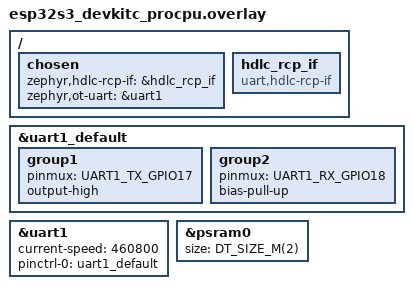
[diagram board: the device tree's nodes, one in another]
/*
 * Copyright (c) 2026 Espressif Systems (Shanghai) Co., Ltd.
 *
 * SPDX-License-Identifier: Apache-2.0
 */

/ {
	chosen {
		zephyr,hdlc-rcp-if = &hdlc_rcp_if;
		zephyr,ot-uart = &uart1;
	};

	hdlc_rcp_if: hdlc_rcp_if {
		compatible = "uart,hdlc-rcp-if";
	};
};

&uart1_default {
	group1 {
		pinmux = <UART1_TX_GPIO17>;
		output-high;
	};

	group2 {
		pinmux = <UART1_RX_GPIO18>;
		bias-pull-up;
	};
};

&uart1 {
	status = "okay";
	current-speed = <460800>;
	pinctrl-0 = <&uart1_default>;
	pinctrl-names = "default";
};

&psram0 {
	size = <DT_SIZE_M(2)>;
};
